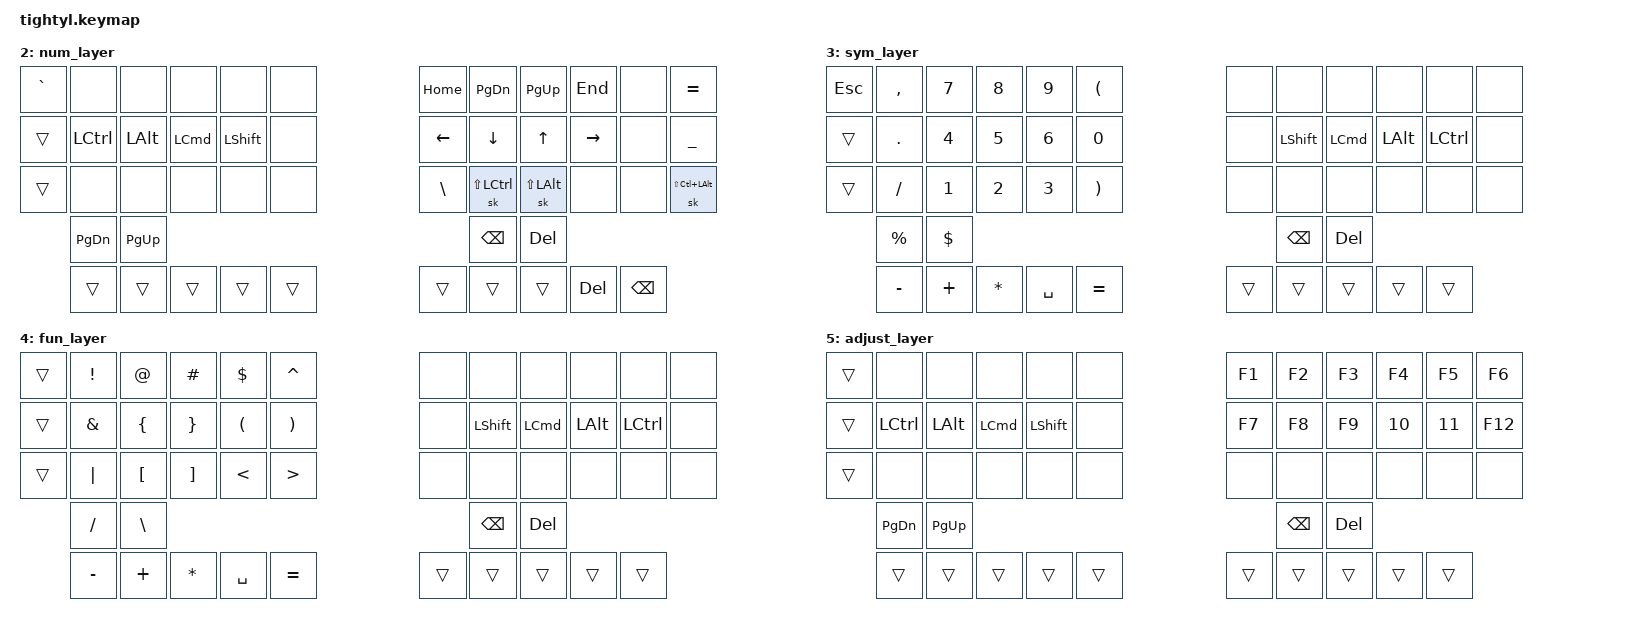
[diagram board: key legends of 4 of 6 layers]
#include "includes/keypos_tightyl.h"

#define KEYS_L LT0 LT1 LT2 LT3 LT4 LT5 LM0 LM1 LM2 LM3 LM4 LM5 LB0 LB1 LB2 LB3 LB4 LB5 LF0 LF1
#define KEYS_R RT0 RT1 RT2 RT3 RT4 RT5 RM0 RM1 RM2 RM3 RM4 RM5 RB0 RB1 RB2 RB3 RB4 RB5 RF0 RF1
#define KEYS_T LH4 LH3 LH2 LH1 LH0 RH0 RH1 RH2 RH3 RH4 

#include <behaviors.dtsi>
#include <dt-bindings/zmk/keys.h>
#include <dt-bindings/zmk/bt.h>
#include <dt-bindings/zmk/outputs.h>
#include "includes/settings.dtsi"
#include "includes/behaviours_homerow_mods.dtsi"

#define DEFAULT 0
#define NAV     1
#define NUM     2 
#define SYM     3
#define FUN     4
#define ADJUST  5

#define HYPER(key) LS(LC(LA(LG(key))))
#define MEH(key)   LS(LC(LA(key)))

&sl {
    release-after-ms = <5000>;
};


&kscan0 {
    debounce-press-ms = <30>;
    debounce-release-ms = <30>;
};

/ {
    keymap {
        compatible = "zmk,keymap";

        default_layer {
            bindings = <
    &kp ESC   &kp Q         &kp W          &kp E            &kp R                &kp T       &kp Y     &kp U               &kp I           &kp O        &kp P            &kp MINUS
    &kp LALT  &hm_l LCTRL A &hm_l LALT S   &hm_l LCMD D     &hm_shift_l LSHFT F  &kp G       &kp H     &hm_shift_r RSFT J  &hm_r RCMD K    &hm_r RALT L &hm_r RCTRL SEMI &kp SQT
    &kp LSHFT &kp Z         &kp X          &kp C            &kp V                &kp B       &kp N     &kp M               &kp COMMA       &kp DOT      &kp FSLH         &kp BSLH
                            &mt LCTRL LBKT &lt ADJUST RBKT                                                                 &lt ADJUST LBRC &mt RCTRL RBRC
                            &lt NAV TILDE  &kp SPACE &mt LCTRL TAB              &mt RALT ESC   &mt LSHFT ENTER &lt SYM BSPC  
            >;
        };

        nav_layer {
            bindings = <
    &kp ESC   &kp Q         &kp W          &kp E            &kp R                &kp T       &kp Y     &kp U               &kp I           &kp O        &kp P            &kp MINUS
    &kp LALT  &hm_l LCTRL A &hm_l LALT S   &hm_l LCMD D     &hm_shift_l LSHFT F  &kp G       &kp H     &hm_shift_r RSFT J  &hm_r RCMD K    &hm_r RALT L &hm_r RCTRL SEMI &kp SQT
    &kp LSHFT &kp Z         &kp X          &kp C            &kp V                &kp B       &kp N     &kp M               &kp COMMA       &kp DOT      &kp FSLH         &kp BSLH
                            &mt LCTRL LBKT &lt ADJUST RBKT                                                                 &lt ADJUST LBRC &mt RCTRL RBRC
                            &lt NAV TILDE  &kp SPACE &mt LCTRL TAB              &mt RALT ESC   &mt LSHFT ENTER &lt SYM BSPC  
            >;
        };

        num_layer {
            bindings = <
    &kp GRAVE &none     &none    &none      &none     &none                              &kp HOME  &kp PG_DN   &kp PG_UP        &kp END    &none    &kp EQUAL
    &trans    &kp LCTRL &kp LALT &kp LCMD   &kp LSHFT &none                              &kp LEFT  &kp DOWN    &kp UP           &kp RIGHT  &none    &kp UNDER
    &trans    &none     &none    &none      &none     &none                              &kp BSLH  &sk LS(LCTRL)  &sk LS(LALT)  &none      &none    &sk LS(LC(LALT))
              &kp PG_DN &kp PG_UP                                                                     &kp BSPC  &kp DEL
              &trans &trans &trans &trans &trans                                        &trans   &trans    &trans    &kp DEL   &kp BSPC
            >;
        };

        sym_layer {
            bindings = <
    &kp ESC  &kp COMMA &kp N7   &kp N8  &kp N9   &kp LPAR                                   &none    &none        &none        &none     &none     &none
    &trans   &kp DOT   &kp N4   &kp N5  &kp N6   &kp N0                                     &none    &kp LSHFT    &kp LCMD     &kp LALT  &kp LCTRL &none
    &trans   &kp FSLH  &kp N1   &kp N2  &kp N3   &kp RPAR                                   &none    &none        &none        &none     &none     &none
             &kp PRCNT &kp DLLR                                                                   &kp BSPC  &kp DEL
             &kp MINUS &kp PLUS &kp STAR &kp SPACE &kp EQUAL                            &trans &trans    &trans    &trans   &trans
            >;
        };

        fun_layer {
            bindings = <
    &trans   &kp EXCL  &kp AT   &kp HASH  &kp DLLR   &kp CARET                          &none    &none        &none        &none     &none     &none
    &trans   &kp AMPS  &kp LBRC &kp RBRC  &kp LPAR   &kp RPAR                           &none    &kp LSHFT    &kp LCMD     &kp LALT  &kp LCTRL &none
    &trans   &kp PIPE  &kp LBKT &kp RBKT  &kp LT     &kp GT                             &none    &none        &none        &none     &none     &none
             &kp FSLH  &kp BSLH                                                                   &kp BSPC  &kp DEL
             &kp MINUS &kp PLUS &kp STAR &kp SPACE &kp EQUAL                            &trans &trans    &trans    &trans   &trans
            >;
        };

        adjust_layer {
            bindings = <
    &trans   &none    &none    &none      &none   &none                                &kp F1    &kp F2       &kp F3       &kp F4    &kp F5    &kp F6
    &trans   &kp LCTRL &kp LALT &kp LCMD  &kp LSHFT &none                              &kp F7    &kp F8       &kp F9       &kp 10    &kp 11    &kp F12
    &trans   &none    &none   &none    &none     &none                                 &none    &none        &none        &none     &none     &none
             &kp PG_DN &kp PG_UP                                                                   &kp BSPC  &kp DEL
             &trans &trans &trans &trans &trans                                        &trans &trans    &trans    &trans   &trans
            >;
        };

    };
};
